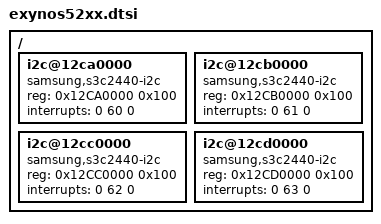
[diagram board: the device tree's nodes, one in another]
/*
 * SAMSUNG Exynos 52xx device tree source
 *
 * Copyright (c) 2013 The Chromium OS Authors.
 * This program is free software; you can redistribute it and/or modify
 * it under the terms of the GNU General Public License version 2 as
 * published by the Free Software Foundation.
 */

/include/ "exynos5.dtsi"
/ {
	i2c@12ca0000 {
		#address-cells = <1>;
		#size-cells = <0>;
		compatible = "samsung,s3c2440-i2c";
		reg = <0x12CA0000 0x100>;
		interrupts = <0 60 0>;
	};

	i2c@12cb0000 {
		#address-cells = <1>;
		#size-cells = <0>;
		compatible = "samsung,s3c2440-i2c";
		reg = <0x12CB0000 0x100>;
		interrupts = <0 61 0>;
	};

	i2c@12cc0000 {
		#address-cells = <1>;
		#size-cells = <0>;
		compatible = "samsung,s3c2440-i2c";
		reg = <0x12CC0000 0x100>;
		interrupts = <0 62 0>;
	};

	i2c@12cd0000 {
		#address-cells = <1>;
		#size-cells = <0>;
		compatible = "samsung,s3c2440-i2c";
		reg = <0x12CD0000 0x100>;
		interrupts = <0 63 0>;
	};
};
